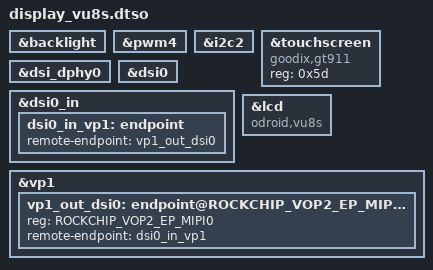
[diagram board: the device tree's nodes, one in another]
/dts-v1/;
/plugin/;

#include <dt-bindings/soc/rockchip,vop2.h>

&backlight {
	status = "okay";
};

&pwm4 {
	status = "okay";
};

&i2c2 {
	status = "okay";
};

&touchscreen {
	compatible = "goodix,gt911";
	reg = <0x5d>;
	status = "okay";
};

&dsi_dphy0 {
	status = "okay";
};

&dsi0 {
	status = "okay";
};

&dsi0_in {
	dsi0_in_vp1: endpoint {
		remote-endpoint = <&vp1_out_dsi0>;
	};
};

&lcd {
	compatible = "odroid,vu8s";
};

&vp1 {
	#address-cells = <1>;
	#size-cells = <0>;

	vp1_out_dsi0: endpoint@ROCKCHIP_VOP2_EP_MIPI0 {
		reg = <ROCKCHIP_VOP2_EP_MIPI0>;
		remote-endpoint = <&dsi0_in_vp1>;
	};
};

